AUTOSAR XML (schema 00044)
package /E40_Platform_System_SystemPackage/Components
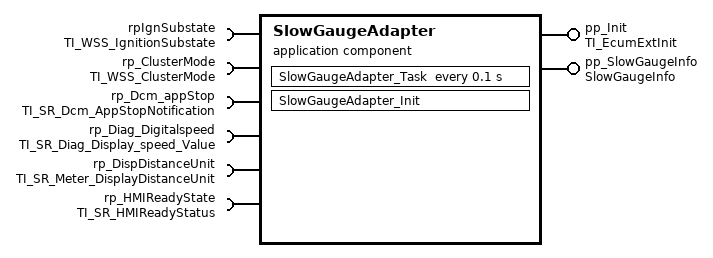
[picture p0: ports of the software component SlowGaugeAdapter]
  application sw component type SlowGaugeAdapter
    provide port pp_Init: server-com-spec{operation=Init, queue-length=1}, provided-interface=TI_EcumExtInit
    provide port pp_SlowGaugeInfo: nonqueued-sender-com-spec{data-element=SlowGaugeInfoData, init-value=constant-reference=SlowGaugeAdapterSlowGaugeInfoDataValue0}, provided-interface=SlowGaugeInfo
    6 x require port:
      rpIgnSubstate: nonqueued-receiver-com-spec{data-element=IgnitionSubstate, filter=data-filter-type=ALWAYS, init-value=constant-reference=SlowGaugeAdapterIgnitionSubstateValue0}, required-interface=TI_WSS_IgnitionSubstate
      rp_ClusterMode: nonqueued-receiver-com-spec{data-element=WSSCurrentClusterMode, filter=data-filter-type=ALWAYS, init-value=constant-reference=SlowGaugeAdapterWSSCurrentClusterModeValue0}, required-interface=TI_WSS_ClusterMode
      rp_Dcm_appStop: nonqueued-receiver-com-spec{data-element=AppId, filter=data-filter-type=ALWAYS, init-value=constant-reference=SlowGaugeAdapterAppIdValue0}, required-interface=TI_SR_Dcm_AppStopNotification
      rp_Diag_Digitalspeed: nonqueued-receiver-com-spec{data-element=Diag_Digital_Speed_Value, filter=data-filter-type=ALWAYS, init-value=constant-reference=SlowGaugeAdapterDiag_Digital_Speed_ValueValue0}, required-interface=TI_SR_Diag_Display_speed_Value
      rp_DispDistanceUnit: nonqueued-receiver-com-spec{data-element=DisplayUnit, filter=data-filter-type=ALWAYS, init-value=constant-reference=SlowGaugeAdapterDisplayUnitValue0}, required-interface=TI_SR_Meter_DisplayDistanceUnit
      rp_HMIReadyState: nonqueued-receiver-com-spec{data-element=HMI_ReadyStatus, filter=data-filter-type=ALWAYS, init-value=constant-reference=SlowGaugeAdapterHMI_ReadyStatusValue0}, required-interface=TI_SR_HMIReadyStatus
    behavior IB_SlowGaugeAdapter
      operation invoked event OIE_pp_Init_SlowGaugeAdapter_InitTrigByInit: start-on-event=SlowGaugeAdapter_Init, operation=pp_Init.Init
      timing event TESlowGaugeAdapter_Task: start-on-event=SlowGaugeAdapter_Task, period=0.1
      port-api-options:
        enable-take-address=false, error-handling=NO-TRANSFORMER-ERROR-HANDLING, indirect-api=false, port=pp_Init
        enable-take-address=false, error-handling=NO-TRANSFORMER-ERROR-HANDLING, indirect-api=false, port=pp_SlowGaugeInfo
        enable-take-address=false, error-handling=NO-TRANSFORMER-ERROR-HANDLING, indirect-api=false, port=rpIgnSubstate
        enable-take-address=false, error-handling=NO-TRANSFORMER-ERROR-HANDLING, indirect-api=false, port=rp_ClusterMode
        enable-take-address=false, error-handling=NO-TRANSFORMER-ERROR-HANDLING, indirect-api=false, port=rp_Dcm_appStop
        enable-take-address=false, error-handling=NO-TRANSFORMER-ERROR-HANDLING, indirect-api=false, port=rp_Diag_Digitalspeed
        enable-take-address=false, error-handling=NO-TRANSFORMER-ERROR-HANDLING, indirect-api=false, port=rp_DispDistanceUnit
        enable-take-address=false, error-handling=NO-TRANSFORMER-ERROR-HANDLING, indirect-api=false, port=rp_HMIReadyState
      runnable SlowGaugeAdapter_Init: can-be-invoked-concurrently=true
      runnable SlowGaugeAdapter_Task: can-be-invoked-concurrently=true
        data-receive-point-by-arguments:
          6 x access:
            DRA_rpIgnSubstate_IgnitionSubstate: accessed-variable=rpIgnSubstate.IgnitionSubstate
            DRA_rp_ClusterMode_WSSCurrentClusterMode: accessed-variable=rp_ClusterMode.WSSCurrentClusterMode
            DRA_rp_Dcm_appStop_AppId: accessed-variable=rp_Dcm_appStop.AppId
            DRA_rp_Diag_Digitalspeed_Diag_Digital_Speed_Value: accessed-variable=rp_Diag_Digitalspeed.Diag_Digital_Speed_Value
            DRA_rp_DispDistanceUnit_DisplayUnit: accessed-variable=rp_DispDistanceUnit.DisplayUnit
            DRA_rp_HMIReadyState_HMI_ReadyStatus: accessed-variable=rp_HMIReadyState.HMI_ReadyStatus
        data-send-points:
          access DWA_pp_SlowGaugeInfo_SlowGaugeInfoData: accessed-variable=pp_SlowGaugeInfo.SlowGaugeInfoData
  swc implementation IMPL_SlowGaugeAdapter: behavior=IB_SlowGaugeAdapter
    code-descriptors:
      code Default: artifact-descriptors=autosar-engineering-object=category=SWSRC
